# DP32G030 register map
File version: 1.0
CPU: CM0 r0p0, little endian, no MPU, no FPU, 4 interrupt priority bits
Registers are 32-bit, read-write, reset 0x0 unless marked. A register's access mark holds for its fields unless they carry their own. Offsets are from the block's base; lines under a group give offsets from that group; [hi:lo] are bit positions; {n}, {i} and the like mark numbered series; 'fields as' and 'values as' point back to an identical list; <NAME> marks a mode.

## Memory map
0x40000000 SYSCON size 0x800 — System Configuration unit
0x40000800 PMU size 0x800 — Power management unit
0x40001000 DMA size 0x800 — DMA unit
0x40003000 CRC size 0x800 — Cyclic redundancy check calculation unit
0x40060000 GPIOA size 0x800 — GPIOA unit
0x40060800 GPIOB size 0x800 — GPIOB unit
0x40061000 GPIOC size 0x800 — GPIOC unit
0x40064000 TIMER_BASE0 size 0x800 — TIMER_BASE0 unit
0x40064800 TIMER_BASE1 size 0x800 — TIMER_BASE1 unit
0x40065000 TIMER_BASE2 size 0x800 — TIMER_BASE2 unit
0x40067000 TIMER_PLUS0 size 0x800 — TIMER_PLUS0 unit
0x40067800 TIMER_PLUS1 size 0x800 — TIMER_PLUS1 unit
0x40069000 RTC size 0x800 — RTC unit
0x4006A000 IWDT size 0x800 — IWDT unit
0x4006A800 WWDT size 0x800 — WWDT unit
0x4006B000 UART0 size 0x800 — UART0 unit
0x4006B800 UART1 size 0x800 — UART1 unit
0x4006C000 UART2 size 0x800 — UART2 unit
0x4006F000 FLASH_CTRL size 0x800 — FLASH_CTRL unit
0x400B0000 PORTCON size 0x800 — PORTCON unit
0x400B1000 PWM_BASE0 size 0x800 — PWM_BASE0 unit
0x400B1800 PWM_BASE1 size 0x800 — PWM_BASE1 unit
0x400B4000 PWM_PLUS0 size 0x800 — PWM_PLUS0 unit
0x400B4800 PWM_PLUS1 size 0x800 — PWM_PLUS1 unit
0x400B8000 SPI0 size 0x800 — SPI0 unit
0x400B8800 SPI1 size 0x800 — SPI1 unit
0x400B9000 IIC0 size 0x800 — IIC0 unit
0x400B9800 IIC1 size 0x800 — IIC1 unit
0x400BA000 SARADC size 0x800 — SARADC unit
0x400BD000 AES128 size 0x800 — AES128 unit

## Interrupts
0 WWDT
1 IWDT
2 RTC
3 DMA
4 SARADC
5 GPIOB0 (GPIOB)
5 TIMER_BASE0
6 TIMER_BASE1
7 TIMER_PLUS0
8 TIMER_PLUS1
9 PWM_BASE0
10 PWM_BASE1
11 PWM_PLUS0
12 PWM_PLUS1
13 UART0
14 UART1
15 UART2
16 SPI0
17 SPI1
18 IIC0
19 IIC1
21 TIMER_BASE2
22 GPIOA5 (GPIOA)
23 GPIOA6 (GPIOA)
24 GPIOA7 (GPIOA)
26 GPIOB1 (GPIOB)
27 GPIOC0 (GPIOC)
28 GPIOC1 (GPIOC)
29 GPIOA
30 GPIOB
31 GPIOC

## CRC — Cyclic redundancy check calculation unit
Base 0x40003000
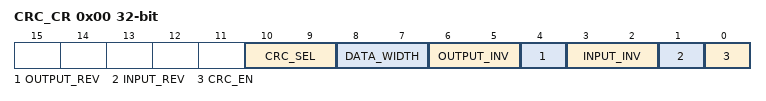
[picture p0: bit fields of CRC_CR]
0x00 CRC_CR — CRC control register
  [10:9] CRC_SEL — CRC Algorithm Selection Register 00: x^16+x^12+x^5+1 01: x^8+x^2+x+1 10: x^16+x^15+x^2+1 11: x^32+x^26+x^23+x^22+x^16+x^12+x^11+x^10+x^8+x^7+x^5+x^4+x^2+x^1+1
  [8:7] DATA_WIDTH — CRC Input Data Valid Bits Register 00: 32-bit input data valid 01: Low 16-bit input data valid 10: Low 8-bit input data valid
  [6:5] OUTPUT_INV — Output Data Flip-Flop Register Flip-Flop Rule Same as INPUT_INV
  [4] OUTPUT_REV — Whether the output data is inverted or not 1: Inversion of output data 0: Output data is not inverted
  [3:2] INPUT_INV — Input data flip-flop register 00: bit order unchanged 01: bit order completely flipped
  [1] INPUT_REV — Whether the input data is inverted or not 1: Input data inversion 0: Input data is not inverted
  [0] CRC_EN — CRC enable bit 1: CRC Enable 0: CRC not enabled
0x04 CRC_IV access not given — CRC initial value register
0x08 CRC_DATAIN access not given — CRC input data register
0x0C CRC_DATAOUT access not given — CRC output data register

## GPIOA — GPIOA unit
Base 0x40060000
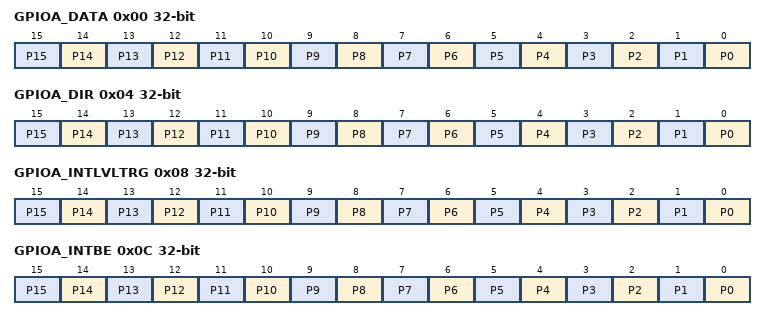
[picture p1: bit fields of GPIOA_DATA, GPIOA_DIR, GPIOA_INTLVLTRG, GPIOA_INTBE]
0x00 GPIOA_DATA — GPIO DATA register
  [n] P{n} (n=0..15)
0x04 GPIOA_DIR — GPIO Pin direction
  [n] P{n} (n=0..15) — Sets the GPIO pin direction: 1: Set the GPIO pin of the corresponding bit as output pin 0: Set the GPIO pin of the corresponding bit as input pin
0x08 GPIOA_INTLVLTRG — GPIO Pin interrupt sensitive conditions
  [n] P{n} (n=0..15) — Sets the GPIO pin interrupt sensitivity condition: 1: Set the GPIO pin of the corresponding bit as level detection 0: Set the GPIO pin of the corresponding bit as Along Detect
0x0C GPIOA_INTBE — GPIO Pin edge trigger mode
  [n] P{n} (n=0..15) — Sets the GPIO pin edge trigger method: 1: Set the GPIO pin of the corresponding bit to double- edge triggered interrupt, i.e., both the rising and falling edges will trigger the interrupt 0: Set the GPIO pin of the corresponding bit to single-edge trigger interrupt, the corresponding bit of INTRISEEN register determines the rising/falling edge trigger.
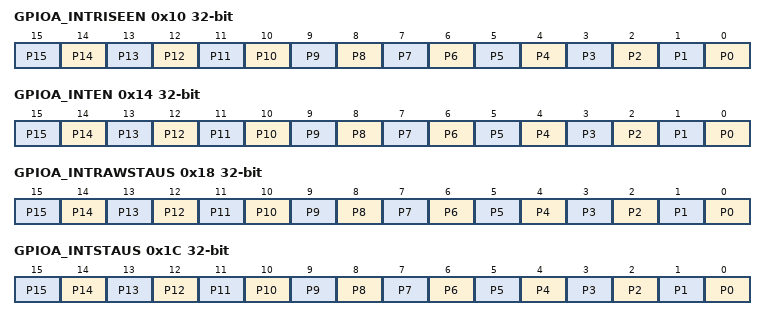
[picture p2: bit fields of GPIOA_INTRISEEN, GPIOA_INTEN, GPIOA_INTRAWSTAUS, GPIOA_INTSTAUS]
0x10 GPIOA_INTRISEEN — GPIO Pin interrupt event mode
  [n] P{n} (n=0..15) — Sets the GPIO pin interrupt event mode: 1: Set the GPIO pin of the corresponding bit to trigger an interrupt with a rising edge/high level. 0: Set the GPIO pin of the corresponding bit as falling edge/low level trigger interrupt
0x14 GPIOA_INTEN — GPIO Pin interrupt enable
  [n] P{n} (n=0..15) — Sets the GPIO pin interrupt enable: 1: Set the GPIO pin interrupt enable for the corresponding bit. 0: Set the GPIO pin interrupt disable for the corresponding bit.
0x18 GPIOA_INTRAWSTAUS ro — Indicates that the corresponding bit is detectedGPIO interrupt trigger
  [n] P{n} (n=0..15) — When the GPIO is configured in input mode, the interrupt flag is generated according to the set trigger condition, independent of the interrupt enable register. Set by hardware and cleared by software by writing 1 to GPIOIC. 1: Indicates that the GPIO interrupt trigger condition for the corresponding bit is detected (raw, before mask) 0: Indicates that no GPIO interrupt trigger condition is detected for the corresponding bit.
0x1C GPIOA_INTSTAUS ro — Indicates that the corresponding bit is detectedGPIO pin generation int
  [n] P{n} (n=0..15) — When the GPIO is configured in input mode and the interrupt of the corresponding bit is enabled, an interrupt flag is generated according to the set trigger condition. It is set by hardware and cleared by software by writing 1 to the GPIOIC. 1: Indicates that an interrupt generated by the GPIO pin of the corresponding bit is detected (after the mask) 0: Indicates that no interrupt generated by the GPIO pin of the corresponding bit is detected
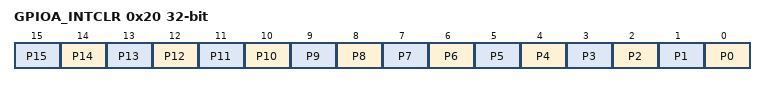
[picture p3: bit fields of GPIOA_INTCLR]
0x20 GPIOA_INTCLR wo — Clear the corresponding bitGPIOsPin edge triggered interrupt flag
  [n] P{n} (n=0..15) — Write 1: Clear the corresponding bit of GPIO Pin Along Trigger Interrupt Flag. INTRAWSTAUS and INTSTAUS. clear interrupts After the flag, the corresponding bit of INTCLR is automatically restored to 0 by the hardware. Write 0: no effect. A read operation on this register returns 0.

## GPIOB — GPIOB unit
Base 0x40060800
Registers as GPIOA (with GPIOA read as GPIOB).
